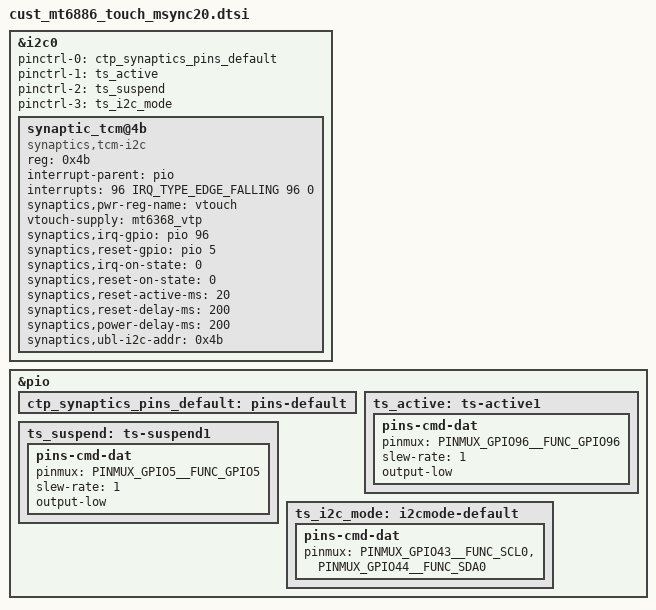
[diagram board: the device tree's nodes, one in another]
// SPDX-License-Identifier: (GPL-2.0 OR MIT)
/*
 * Copyright (C) 2020 MediaTek Inc.
 */

/* TOUCH start */
&i2c0 {
	#address-cells = <1>;
	#size-cells = <0>;
	status = "ok";
	pinctrl-names = "default", "pmx_ts_active", "pmx_ts_suspend", "pmx_ts_i2c_mode";
	pinctrl-0 = <&ctp_synaptics_pins_default>;
	pinctrl-1 = <&ts_active>;
	pinctrl-2 = <&ts_suspend>;
	pinctrl-3 = <&ts_i2c_mode>;

	synaptic_tcm@4b {
		compatible = "synaptics,tcm-i2c";
		reg = <0x4b>;
		interrupt-parent = <&pio>;
		interrupts = <96 IRQ_TYPE_EDGE_FALLING 96 0>;
		//synaptics,bus-reg-name = "vdd";
		//vdd-supply = <&mt6368_vtp>;
		synaptics,pwr-reg-name = "vtouch";
		vtouch-supply = <&mt6368_vtp>;
		synaptics,irq-gpio = <&pio 96 0x2008>;
		synaptics,reset-gpio = <&pio 5 0x0>;
		synaptics,irq-on-state = <0>;
		synaptics,reset-on-state = <0>;
		synaptics,reset-active-ms = <20>;
		synaptics,reset-delay-ms = <200>;
		synaptics,power-delay-ms = <200>;
		synaptics,ubl-i2c-addr = <0x4b>;
		/* tp-io reset is only used for specific tddi devices */
		/* synaptics,tpio-reset-gpio = <&msm_gpio 102 0>; */
	};
};


&pio {
	ctp_synaptics_pins_default: pins-default {
	};
	ts_active: ts-active1 {
		pins-cmd-dat {
			pinmux = <PINMUX_GPIO96__FUNC_GPIO96>;
			slew-rate = <1>;
			output-low;
		};
	};
	ts_suspend: ts-suspend1 {
		pins-cmd-dat {
			pinmux = <PINMUX_GPIO5__FUNC_GPIO5>;
			slew-rate = <1>;
			output-low;
		};
	};
	ts_i2c_mode: i2cmode-default {
		pins-cmd-dat {
			pinmux = <PINMUX_GPIO43__FUNC_SCL0>,
				<PINMUX_GPIO44__FUNC_SDA0>;
		};
	};
};
/* TOUCH end */
